# Montana register map
Vendor: ONSemiconductor; Series: Montana Series; File version: 1.0
CPU: CM33 r0p4, little endian, MPU, FPU, 3 interrupt priority bits
Registers are 32-bit, read-write, reset 0x0 unless marked. A register's access mark holds for its fields unless they carry their own. Offsets are from the block's base; [hi:lo] are bit positions; lines under a group give offsets from that group.

## SCB — System Control Block
Base 0xE000ED00
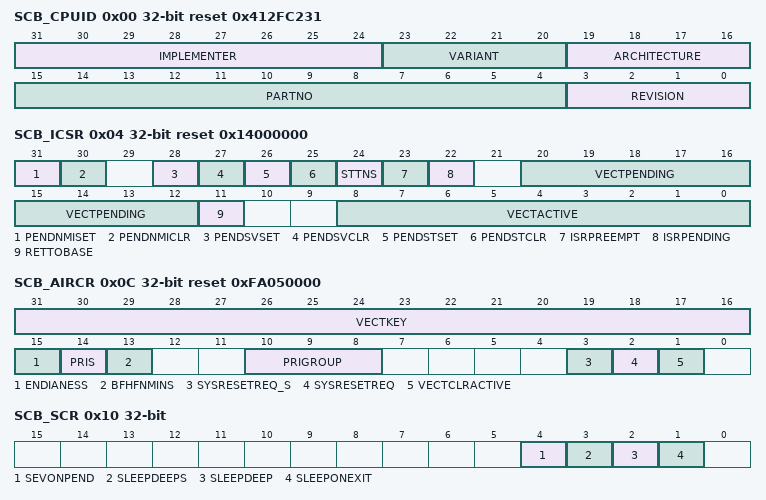
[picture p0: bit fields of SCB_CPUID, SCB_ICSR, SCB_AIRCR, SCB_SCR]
0x00 SCB_CPUID ro reset 0x412FC231 — CPU ID Base Register
  [31:24] IMPLEMENTER — Implementer code
  [23:20] VARIANT — Implementation variant
  [19:16] ARCHITECTURE — Architecture number
  [15:4] PARTNO — Part number
  [3:0] REVISION — Revision code
0x04 SCB_ICSR reset 0x14000000 (reset mask 0x95DFF9FF) — Interrupt Control and State Register
  [31] PENDNMISET — Sets the NMI exception pending
    0=NMI_NOT_PENDING (Set NMI exception to pending); 1=NMI_SETPEND
  [30] PENDNMICLR wo — Pend NMI clear
    1=CLR_NMI_PENDING_STATUS
  [28] PENDSVSET — Write 1 to set pending status for PendSV exception. Read indicates PendSV pending status
    1=PENDSV_SETPEND (Set PendSV exception to pending)
  [27] PENDSVCLR wo — Write 1 to clear PendSV exception pending status
    1=PENDSV_CLRPEND (Clear PendSV exception pending status)
  [26] PENDSTSET — Write 1 to set pending status for SYSTICK exception. Read value indicates SYSTICK pending status
    1=SYSTICK_SETPEND (Set SYSTICK exception to pending)
  [25] PENDSTCLR wo — Write 1 to clear SYSTICK exception pending status
    1=SYSTICK_CLRPEND (Clear SYSTICK exception pending status)
  [24] STTNS — SysTick target non-secure (RAZ/WI from non-secure state)
    0=SYSTICK_IS_SECURE; 1=SYSTICK_IS_NON_SECURE
  [23] ISRPREEMPT ro — Indicates that a pending interrupt is going to be active in the next step
  [22] ISRPENDING ro — Indicates that an external interrupt is pending
  [20:12] VECTPENDING ro — Pending external interrupt number
  [11] RETTOBASE ro — Set to 1 when the an exception handler is being run.
  [8:0] VECTACTIVE ro — Number of current running interrupt service routine
0x08 SCB_VTOR — Vector Table Offset Register
  [31:7] TBLOFF — Table offset value in code or RAM region. Must be multiple of 128.
0x0C SCB_AIRCR reset 0xFA050000 (reset mask 0xFFFFE708) — Application Interrupt and Reset Control Register
  [31:16] VECTKEY — Access key for writing this register. Must be set to 0x05FA to write the other register fields.
    0x5FA=NVIC_VECTKEY_UNLOCK (Unlocks the NVIC_APP_INT_CTRL register); 0xFA05=NVIC_VECTKEY_UNLOCK_READBACK (Readback value when reading the VECTKEY field after unlocking)
  [15] ENDIANESS ro — Indicates endianess for data.
    0=NVIC_LITTLE_ENDIAN (Indicates core is configured for little endian data)
  [14] PRIS — Prioritize Secure exceptions
    0=IDENTICAL_PRIORITY; 1=NS_EXCEPTION_ARE_DEPRIORITIZED
  [13] BFHFNMINS — BusFault, HardFault and NMI non-secure enable.
    0=BFHFNMI_ARE_SECURE; 1=BFHFNMI_ARE_NONSECURE
  [10:8] PRIGROUP — Priority group setting. Controls how many bits in the priority register are used for pre-empty priority vs. sub-priority.
    0=NVIC_PRIGROUP_0_7 (Indicates 4 bits for pre-emption priority and 0 bits for sub-priority); 3=NVIC_PRIGROUP_4_0 (Indicates 3 bits for pre-emption priority and 1 bit for sub-priority); 4=NVIC_PRIGROUP_3_1 (Indicates 2 bits for pre-emption priority and 2 bits for sub-priority); 5=NVIC_PRIGROUP_2_2 (Indicates 1 bit for pre-emption priority and 3 bits for sub-priority); 6=NVIC_PRIGROUP_1_3 (Indicates 0 bits for pre-emption priority and 4 bits for sub-priority); 7=NVIC_PRIGROUP_0_4
  [3] SYSRESETREQ_S — System reset request secure or non secure config
    0=SYSRESETREQ_FOR_BOTH; 1=SYSRESETREQ_FOR_SECURE_ONLY
  [2] SYSRESETREQ wo — Requests a chip-level system reset
    1=NVIC_SYSRESET (Requests a chjp-level system reset)
  [1] VECTCLRACTIVE wo — Clears all active exception state information
    1=NVIC_CLEAR_ACTIVE_VECTORS (Clears all active exception state information)
0x10 SCB_SCR — System Control Register
  [4] SEVONPEND — Set to 1 to cause the WFE to wake up if a new interrupt is pended
  [3] SLEEPDEEPS — Sleep deep secure state access
    0=SLEEPDEEP_FOR_BOTH; 1=SLEEPDEEP_FOR_SECURE_ONLY
  [2] SLEEPDEEP — Enable SLEEPDEEP output signal when entering sleep mode
    0=NVIC_SLEEPDEEP_DISABLE (Disable SLEEPDEEP output signal when entering sleep mode); 1=NVIC_SLEEPDEEP_ENABLE (Enable SLEEPDEEP output signal when entering sleep mode)
  [1] SLEEPONEXIT — Enable sleep on exit feature when returning from handler to thread mode
    0=NVIC_SLEEPONEXIT_DISABLE (Disable sleep on exit feature); 1=NVIC_SLEEPONEXIT_ENABLE (Enable sleep on exit feature)
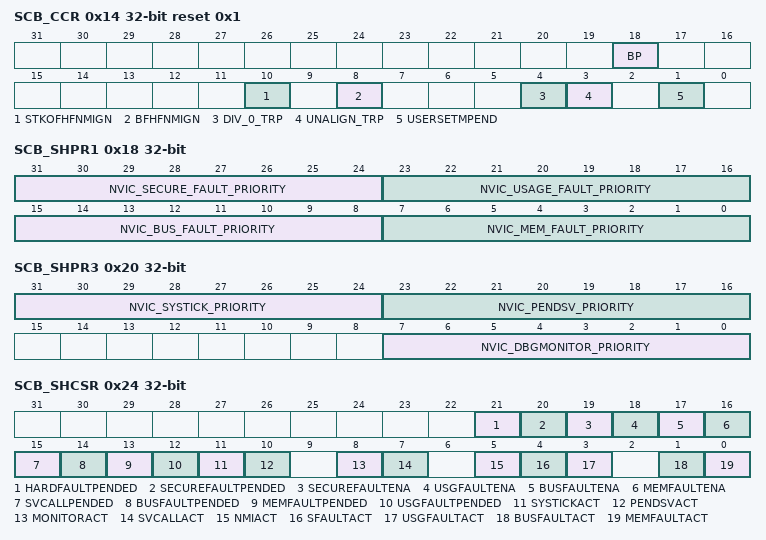
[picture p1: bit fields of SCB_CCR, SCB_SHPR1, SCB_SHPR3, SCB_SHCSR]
0x14 SCB_CCR reset 0x1 — Configuration Control Register
  [18] BP — Branch prediction enable
    0=BP_DISABLED; 1=BP_ENABLED
  [10] STKOFHFNMIGN — Stack overflow in HardFauld and NMI ignore
    0=STACK_FAULT_NOT_IGNORED; 1=STACK_FAULT_IGNORED
  [8] BFHFNMIGN — Ignore data bus faults in hard fault and NMI exceptions
    0=NVIC_BFHFNMIGN_DISABLE (Disable ignoring of data bus faults in hard fault and NMI exception handlers. Bus faults in these handlers will cause lock-up); 1=NVIC_BFHFNMIGN_ENABLE (Enable ignoring of data bus faults in hard fault and NMI exception handlers)
  [4] DIV_0_TRP — Trap on divide by zero
    0=NVIC_DIV_0_TRP_DISABLE (Disable trapping on divide by zero); 1=NVIC_DIV_0_TRP_ENABLE (Enable trapping on divide by zero)
  [3] UNALIGN_TRP — Trap on unaligned data access
    0=NVIC_UNALIGN_TRP_DISABLE (Disable trapping on unaligned data access); 1=NVIC_UNALIGN_TRP_ENABLE (Enable trapping on unaligned data access)
  [1] USERSETMPEND — Allow user code to write to software trigger interrupt register
    0=NVIC_USERSETMPEND_DISABLE (Disable user code access to software trigger interrupt register); 1=NVIC_USERSETMPEND_ENABLE (Enable user code access to software trigger interrupt register)
0x18 SCB_SHPR1 — System Handler Priority Register 1
  [31:24] NVIC_SECURE_FAULT_PRIORITY — Configure the secure fault priority
  [23:16] NVIC_USAGE_FAULT_PRIORITY — Configure the usage fault priority
  [15:8] NVIC_BUS_FAULT_PRIORITY — Configure the bus fault priority
  [7:0] NVIC_MEM_FAULT_PRIORITY — Configure the memory fault priority
0x1C SCB_SHPR2 — System Handler Priority Register 2
  [31:24] NVIC_SVC_PRIORITY — Configure the SVCall priority
0x20 SCB_SHPR3 — System Handler Priority Register 3
  [31:24] NVIC_SYSTICK_PRIORITY — Configure the SysTick interrupt priority
  [23:16] NVIC_PENDSV_PRIORITY — Configure the PendSV priority
  [7:0] NVIC_DBGMONITOR_PRIORITY — Configure the Debug Monitor priority
0x24 SCB_SHCSR — System Handler Control and State Register
  [21] HARDFAULTPENDED ro — Hard fault exception pended state
    0=NVIC_HFAULT_NOT_PENDING; 1=NVIC_HFAULT_PENDING
  [20] SECUREFAULTPENDED ro — Secure fault exception pended state
    0=NVIC_SFAULT_NOT_PENDING; 1=NVIC_SFAULT_PENDING
  [19] SECUREFAULTENA — Secure fault handler enable
    0=NVIC_SFAULT_DISABLE (Disable usage fault handler); 1=NVIC_SFAULT_ENABLE (Enable usage fault handler)
  [18] USGFAULTENA — Usage fault handler enable
    0=NVIC_USGFAULT_DISABLE (Disable usage fault handler); 1=NVIC_USGFAULT_ENABLE (Enable usage fault handler)
  [17] BUSFAULTENA — Bus fault handler enable
    0=NVIC_BUSFAULT_DISABLE (Disable bus fault handler); 1=NVIC_BUSFAULT_ENABLE (Enable bus fault handler)
  [16] MEMFAULTENA — Memory management fault handler enable
    0=NVIC_MEMFAULT_DISABLE (Disable memory management fault handler); 1=NVIC_MEMFAULT_ENABLE (Enable memory management fault handler)
  [15] SVCALLPENDED — SVCall is pending or was started and replaced by a higher priority exception
    0=NVIC_SVCALL_CLRPEND (SVCall handler not pending); 1=NVIC_SVCALL_SETPEND (SVCall handler is pending)
  [14] BUSFAULTPENDED — Bus fault is pending or was started and replaced by a higher priority exception
    0=NVIC_BUSFAULT_CLRPEND (Bus fault handler not pending); 1=NVIC_BUSFAULT_SETPEND (Bus fault handler is pending)
  [13] MEMFAULTPENDED — Memory management fault is pending or was started and replaced by a higher priority exception
    0=NVIC_MEMFAULT_CLRPEND (Memory management fault handler not pending); 1=NVIC_MEMFAULT_SETPEND (Memory management fault handler is pending)
  [12] USGFAULTPENDED — Usage fault is pending or was started and replaced by a higher priority exception
    0=NVIC_USGFAULT_CLRPEND (Usagefault handler not pending); 1=NVIC_USGFAULT_SETPEND (Usage fault handler is pending)
  [11] SYSTICKACT — SYSTICK exception handler is active
    1=NVIC_SYSTICK_ACTIVE (SysTick exception handler is active)
  [10] PENDSVACT — PendSV exception handler is active
    1=NVIC_PENDSV_ACTIVE (PendSV exception handler is active)
  [8] MONITORACT — Debug monitor exception handler is active
    1=NVIC_MONITOR_ACTIVE (Debug monitor exception handler is active)
  [7] SVCALLACT — SVCall exception handler is active
    1=NVIC_SVCALL_ACTIVE (SVCall exception is active)
  [5] NMIACT — NMI exception hangler is active
    1=NVIC_NMI_ACTIVE
  [4] SFAULTACT — Secure fault exception handler is active
    1=NVIC_SFAULT_ACTIVE
  [3] USGFAULTACT — Usage fault exception handler is active
    1=NVIC_USGFAULT_ACTIVE (Usage fault exception handler is active)
  [1] BUSFAULTACT — Bus fault exception handler is active
    1=NVIC_BUSFAULT_ACTIVE (Bus fault exception handler is active)
  [0] MEMFAULTACT — Memory management fault exception handler is active
    1=NVIC_MEMFAULT_ACTIVE (Memory management fault exception handler is active)
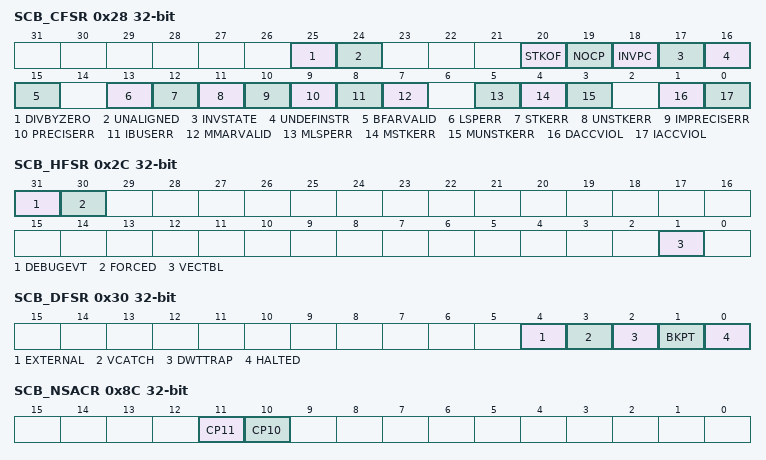
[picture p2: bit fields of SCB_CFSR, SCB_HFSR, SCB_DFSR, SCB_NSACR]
0x28 SCB_CFSR — Configurable Fault Status Register
  [25] DIVBYZERO — Indicates divide by zero will take place
  [24] UNALIGNED — Indicates unaligned access will take place
  [20] STKOF — Stack overflow flag
  [19] NOCP — Attempt to execute a coprocessor instruction
  [18] INVPC — Attempt to do exception with bad value in EXC_RETURN number
  [17] INVSTATE — Attempt to switch to invalid (e.g. ARM) state
  [16] UNDEFINSTR — Attempt to execute an undefined instruction
  [15] BFARVALID ro — Indicates if bus fault address register is valid
  [13] LSPERR ro — Lazy state preservation error
  [12] STKERR — Indicates stacking error
  [11] UNSTKERR — Indicates unstacking error
  [10] IMPRECISERR — Indicates imprecise data access violation
  [9] PRECISERR — Indicates precise data access violation
  [8] IBUSERR — Indicates instruction access violation
  [7] MMARVALID ro — Indicates if memory management fault address register is valid
  [5] MLSPERR ro — Inidicates if memory management lazy state preservation error flag
  [4] MSTKERR — Indicates stacking error
  [3] MUNSTKERR — Indicates unstacking error
  [1] DACCVIOL — Indicates data access violation
  [0] IACCVIOL — Indicates instruction access violation
0x2C SCB_HFSR — Hard Fault Status Register
  [31] DEBUGEVT — Indicates hard fault is triggered by debug event
  [30] FORCED — Indicates hard fault is taken because of a lower priority (e.g., bus, memory management or usage) fault
  [1] VECTBL — Indicates hard fault is taken due to failed vector fetch
0x30 SCB_DFSR — Debug Fault Status Register
  [4] EXTERNAL — Indicates external debug request signal asserted
  [3] VCATCH — Indicates vector fetch occurred
  [2] DWTTRAP — Indicates DWT match occurred
  [1] BKPT — Indicates BKPT instruction executed
  [0] HALTED — Indicates halt requested by NVIC
0x34 SCB_MMFAR ro — Memory Management Fault Address Register
  [31:0] NVIC_MMAR — Memory Management address
0x38 SCB_BFAR ro — Bus Fault Address Register
  [31:0] NVIC_BFAR — Bus Fault address
0x8C SCB_NSACR — Non-Secure Access Control Register
  [11] CP11 ro — Enable non-secure access to the Floating-point extension
  [10] CP10 — Enables Non-secure access to the Floating-point Extension
    0=NS_ACCESS_TO_FPE_UF (Non-secure accesses to the Floating-point Extension generate a NOCP UsageFault); 1=NS_ACCESS_TO_FPE_ALLOW (Non-secure access to the Floating-point Extension permitted)
